# Cortex_A35 register map
Vendor: ARM Ltd.; File version: 1.1
Registers are 32-bit, read-write, no defined reset value unless marked. A register's access mark holds for its fields unless they carry their own. Offsets are from the block's base; [hi:lo] are bit positions; {n}, {i} and the like mark numbered series; 'fields as' and 'values as' point back to an identical list.

## ETM0
Base 0x4A240000
Same registers: ETM1 0x4A340000
0x04 TRC_PRGCTLR
  [0] EN — Name of field: EN
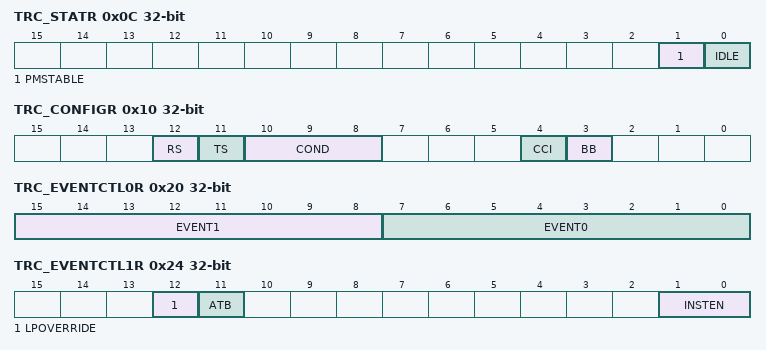
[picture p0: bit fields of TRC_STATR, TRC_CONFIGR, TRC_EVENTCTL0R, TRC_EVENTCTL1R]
0x0C TRC_STATR
  [1] PMSTABLE — Name of field: PMSTABLE
  [0] IDLE — Name of field: IDLE
0x10 TRC_CONFIGR
  [12] RS — Name of field: RS
  [11] TS — Name of field: TS
  [10:8] COND — Name of field: COND
  [4] CCI — Name of field: CCI
  [3] BB — Name of field: BB
0x20 TRC_EVENTCTL0R
  [15:8] EVENT1 — Name of field: EVENT1
  [7:0] EVENT0 — Name of field: EVENT0
0x24 TRC_EVENTCTL1R
  [12] LPOVERRIDE — Name of field: LPOVERRIDE
  [11] ATB — Name of field: ATB
  [1:0] INSTEN — Name of field: INSTEN
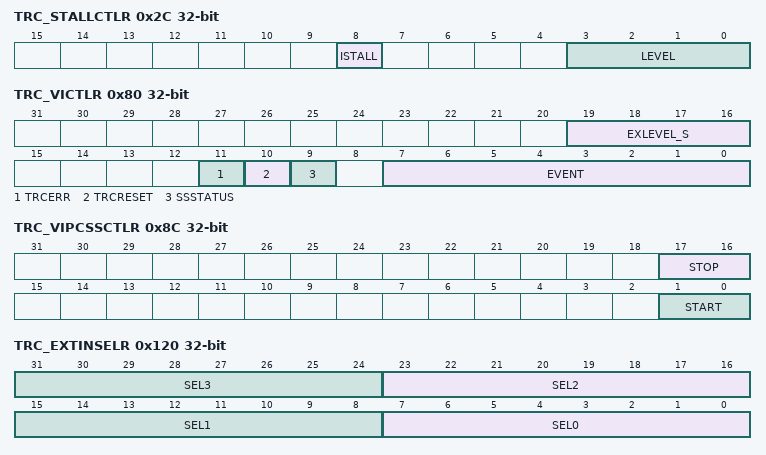
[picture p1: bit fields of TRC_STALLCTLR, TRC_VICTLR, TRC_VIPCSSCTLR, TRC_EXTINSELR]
0x2C TRC_STALLCTLR
  [8] ISTALL — Name of field: ISTALL
  [3:0] LEVEL — Name of field: LEVEL
0x30 TRC_TSCTLR
  [7:0] EVENT — Name of field: EVENT
0x34 TRC_SYNCPR
  [4:0] PERIOD — Name of field: PERIOD
0x38 TRC_CCCTLR
  [11:0] THRESHOLD — Name of field: THRESHOLD
0x40 TRC_TRACEIDR
  [6:0] TRACEID — Name of field: TRACEID
0x80 TRC_VICTLR
  [19:16] EXLEVEL_S — Name of field: EXLEVEL_S
  [11] TRCERR — Name of field: TRCERR
  [10] TRCRESET — Name of field: TRCRESET
  [9] SSSTATUS — Name of field: SSSTATUS
  [7:0] EVENT — Name of field: EVENT
0x8C TRC_VIPCSSCTLR
  [17:16] STOP — Name of field: STOP
  [1:0] START — Name of field: START
0x120 TRC_EXTINSELR
  [8n+7:8n] SEL{n} (n=0..3) — Name of field: SEL{n}
0x140 TRC_CNTRLDVR0
  [15:0] VALUE — Name of field: VALUE
0x180 TRC_IDR8
  [31:0] MAXSPEC — Name of field: MAXSPEC
0x184 TRC_IDR9
  [31:0] NUMP0KEY — Name of field: NUMP0KEY
0x188 TRC_IDR10
  [31:0] NUMP1KEY — Name of field: NUMP1KEY
0x18C TRC_IDR11
  [31:0] NUMP1SPC — Name of field: NUMP1SPC
0x190 TRC_IDR12
  [31:0] NUMCONDKEY — Name of field: NUMCONDKEY
0x194 TRC_IDR13
  [31:0] NUMCONDSPC — Name of field: NUMCONDSPC
0x1C0 TRC_IMSPEC0
  [3:0] SUPPORT — Name of field: SUPPORT
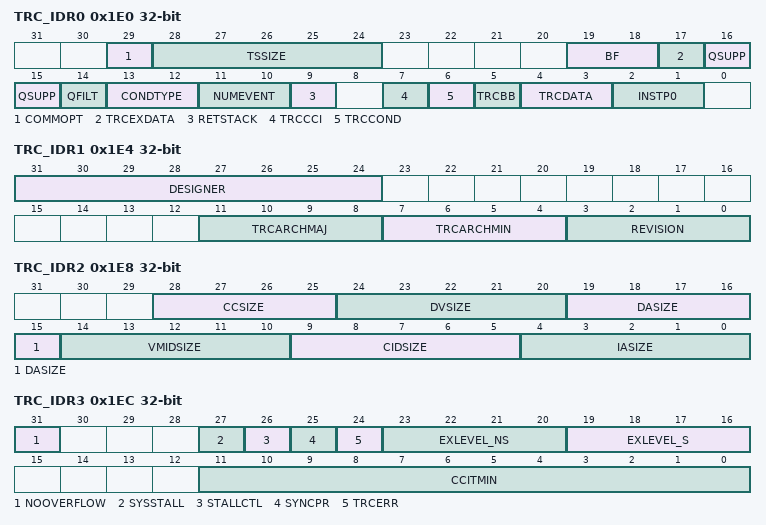
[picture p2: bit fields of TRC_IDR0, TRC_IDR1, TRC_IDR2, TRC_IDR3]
0x1E0 TRC_IDR0
  [29] COMMOPT — Name of field: COMMOPT
  [28:24] TSSIZE — Name of field: TSSIZE
  [19:18] BF — Name of field: BF
  [17] TRCEXDATA — Name of field: TRCEXDATA
  [16:15] QSUPP — Name of field: QSUPP
  [14] QFILT — Name of field: QFILT
  [13:12] CONDTYPE — Name of field: CONDTYPE
  [11:10] NUMEVENT — Name of field: NUMEVENT
  [9] RETSTACK — Name of field: RETSTACK
  [7] TRCCCI — Name of field: TRCCCI
  [6] TRCCOND — Name of field: TRCCOND
  [5] TRCBB — Name of field: TRCBB
  [4:3] TRCDATA — Name of field: TRCDATA
  [2:1] INSTP0 — Name of field: INSTP0
0x1E4 TRC_IDR1
  [31:24] DESIGNER — Name of field: DESIGNER
  [11:8] TRCARCHMAJ — Name of field: TRCARCHMAJ
  [7:4] TRCARCHMIN — Name of field: TRCARCHMIN
  [3:0] REVISION — Name of field: REVISION
0x1E8 TRC_IDR2
  [28:25] CCSIZE — Name of field: CCSIZE
  [24:20] DVSIZE — Name of field: DVSIZE
  [19:15] DASIZE — Name of field: DASIZE
  [14:10] VMIDSIZE — Name of field: VMIDSIZE
  [9:5] CIDSIZE — Name of field: CIDSIZE
  [4:0] IASIZE — Name of field: IASIZE
0x1EC TRC_IDR3
  [31] NOOVERFLOW — Name of field: NOOVERFLOW
  [27] SYSSTALL — Name of field: SYSSTALL
  [26] STALLCTL — Name of field: STALLCTL
  [25] SYNCPR — Name of field: SYNCPR
  [24] TRCERR — Name of field: TRCERR
  [23:20] EXLEVEL_NS — Name of field: EXLEVEL_NS
  [19:16] EXLEVEL_S — Name of field: EXLEVEL_S
  [11:0] CCITMIN — Name of field: CCITMIN
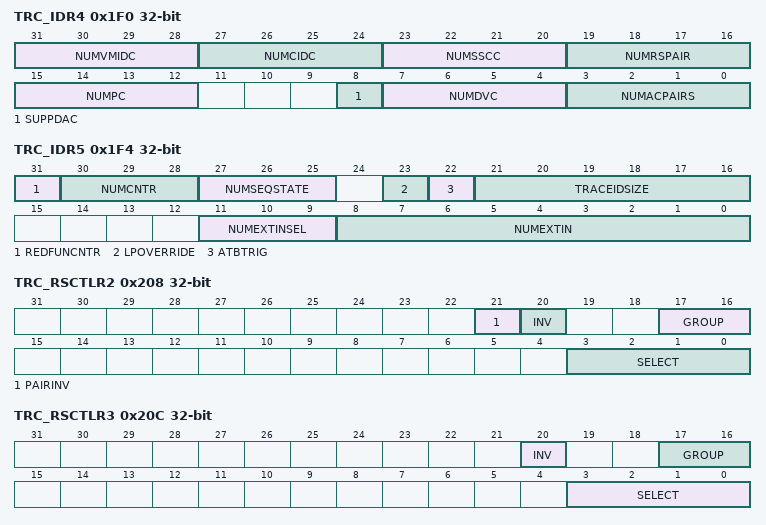
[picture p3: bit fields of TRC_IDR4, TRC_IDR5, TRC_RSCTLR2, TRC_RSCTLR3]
0x1F0 TRC_IDR4
  [31:28] NUMVMIDC — Name of field: NUMVMIDC
  [27:24] NUMCIDC — Name of field: NUMCIDC
  [23:20] NUMSSCC — Name of field: NUMSSCC
  [19:16] NUMRSPAIR — Name of field: NUMRSPAIR
  [15:12] NUMPC — Name of field: NUMPC
  [8] SUPPDAC — Name of field: SUPPDAC
  [7:4] NUMDVC — Name of field: NUMDVC
  [3:0] NUMACPAIRS — Name of field: NUMACPAIRS
0x1F4 TRC_IDR5
  [31] REDFUNCNTR — Name of field: REDFUNCNTR
  [30:28] NUMCNTR — Name of field: NUMCNTR
  [27:25] NUMSEQSTATE — Name of field: NUMSEQSTATE
  [23] LPOVERRIDE — Name of field: LPOVERRIDE
  [22] ATBTRIG — Name of field: ATBTRIG
  [21:16] TRACEIDSIZE — Name of field: TRACEIDSIZE
  [11:9] NUMEXTINSEL — Name of field: NUMEXTINSEL
  [8:0] NUMEXTIN — Name of field: NUMEXTIN
0x208 TRC_RSCTLR2
  [21] PAIRINV — Name of field: PAIRINV
  [20] INV — Name of field: INV
  [17:16] GROUP — Name of field: GROUP
  [3:0] SELECT — Name of field: SELECT
0x20C TRC_RSCTLR3
  [20] INV — Name of field: INV
  [17:16] GROUP — Name of field: GROUP
  [3:0] SELECT — Name of field: SELECT
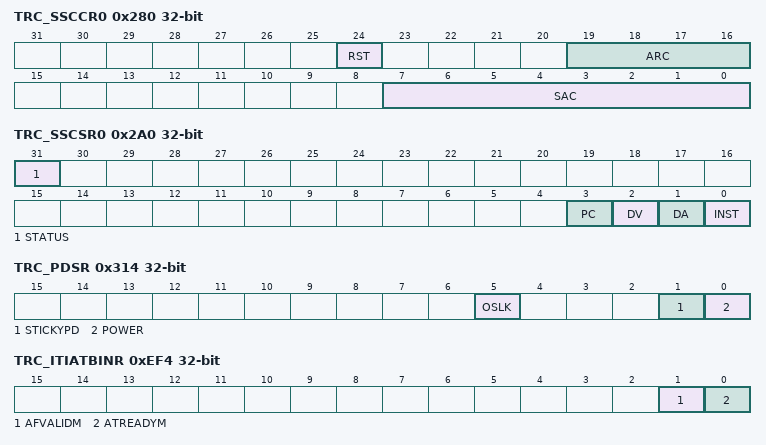
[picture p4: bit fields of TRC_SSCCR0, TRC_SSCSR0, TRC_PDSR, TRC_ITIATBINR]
0x280 TRC_SSCCR0
  [24] RST — Name of field: RST
  [19:16] ARC — Name of field: ARC
  [7:0] SAC — Name of field: SAC
0x2A0 TRC_SSCSR0
  [31] STATUS — Name of field: STATUS
  [3] PC — Name of field: PC
  [2] DV — Name of field: DV
  [1] DA — Name of field: DA
  [0] INST — Name of field: INST
0x2C0 TRC_SSPCICR0
  [3:0] PC — Name of field: PC
0x310 TRC_PDCR
  [3] PU — Name of field: PU
0x314 TRC_PDSR
  [5] OSLK — Name of field: OSLK
  [1] STICKYPD — Name of field: STICKYPD
  [0] POWER — Name of field: POWER
0xEE4 TRC_ITATBIDR
  [6:0] ID — Name of field: ID
0xEEC TRC_ITIDATAR
  [6:0] DATA — Name of field: DATA
0xEF4 TRC_ITIATBINR
  [1] AFVALIDM — Name of field: AFVALIDM
  [0] ATREADYM — Name of field: ATREADYM
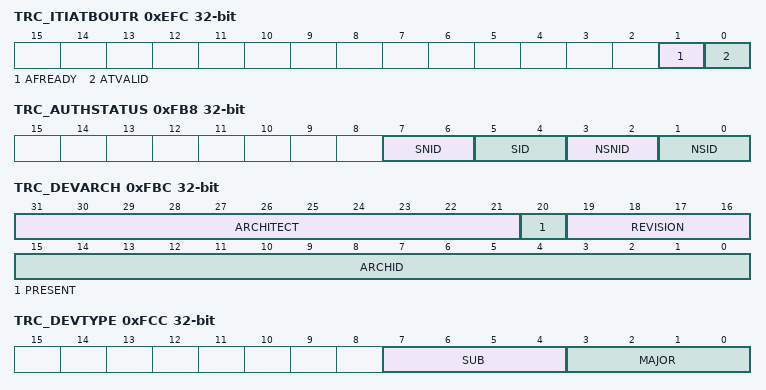
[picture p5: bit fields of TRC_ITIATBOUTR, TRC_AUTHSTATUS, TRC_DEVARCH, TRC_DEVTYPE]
0xEFC TRC_ITIATBOUTR
  [1] AFREADY — Name of field: AFREADY
  [0] ATVALID — Name of field: ATVALID
0xF00 TRC_ITCTRL
  [0] IME — Name of field: IME
0xFA0 TRC_CLAIMSET
  [3:0] SET — Name of field: SET
0xFA4 TRC_CLAIMCLR
  [3:0] CLR — Name of field: CLR
0xFB8 TRC_AUTHSTATUS
  [7:6] SNID — Name of field: SNID
  [5:4] SID — Name of field: SID
  [3:2] NSNID — Name of field: NSNID
  [1:0] NSID — Name of field: NSID
0xFBC TRC_DEVARCH
  [31:21] ARCHITECT — Name of field: ARCHITECT
  [20] PRESENT — Name of field: PRESENT
  [19:16] REVISION — Name of field: REVISION
  [15:0] ARCHID — Name of field: ARCHID
0xFCC TRC_DEVTYPE
  [7:4] SUB — Name of field: SUB
  [3:0] MAJOR — Name of field: MAJOR
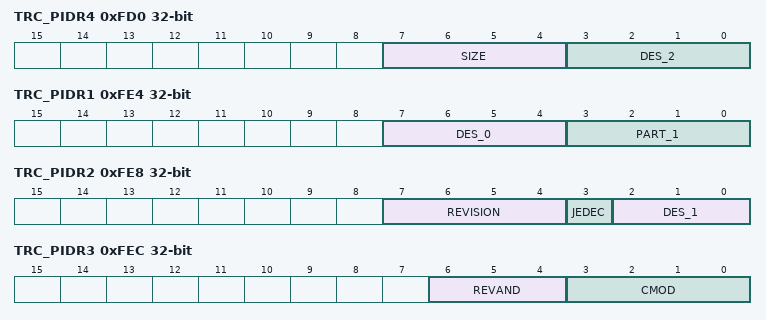
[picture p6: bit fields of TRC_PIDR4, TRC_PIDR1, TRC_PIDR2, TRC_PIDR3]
0xFD0 TRC_PIDR4
  [7:4] SIZE — Name of field: SIZE
  [3:0] DES_2 — Name of field: DES_2
0xFE0 TRC_PIDR0
  [7:0] PART_0 — Name of field: PART_0
0xFE4 TRC_PIDR1
  [7:4] DES_0 — Name of field: DES_0
  [3:0] PART_1 — Name of field: PART_1
0xFE8 TRC_PIDR2
  [7:4] REVISION — Name of field: REVISION
  [3] JEDEC — Name of field: JEDEC
  [2:0] DES_1 — Name of field: DES_1
0xFEC TRC_PIDR3
  [6:4] REVAND — Name of field: REVAND
  [3:0] CMOD — Name of field: CMOD

## PMU0
Base 0x4A230000
Same registers: PMU1 0x4A330000
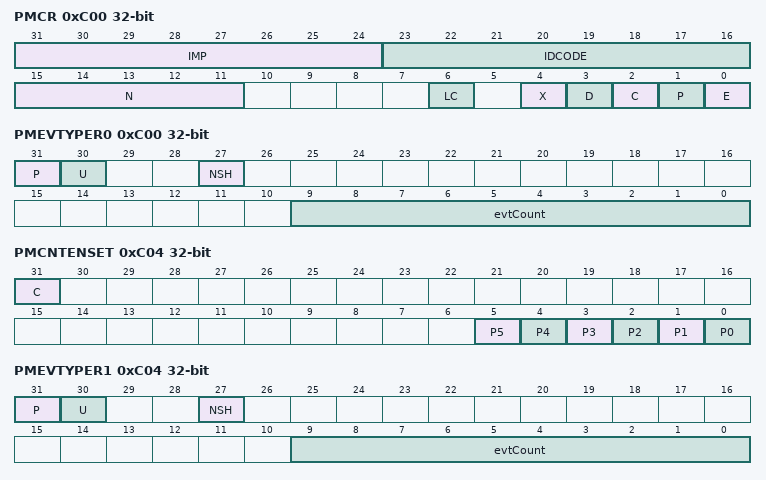
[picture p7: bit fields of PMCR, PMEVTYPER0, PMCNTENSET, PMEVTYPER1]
0xC00 PMCR
  [31:24] IMP — Name of field: IMP
  [23:16] IDCODE — Name of field: IDCODE
  [15:11] N — Name of field: N
  [6] LC — Name of field: LC
  [4] X — Name of field: X
  [3] D — Name of field: D
  [2] C — Name of field: C
  [1] P — Name of field: P
  [0] E — Name of field: E
0xC00 PMEVTYPER0 (alternate view of PMCR)
  [31] P — Name of field: P
  [30] U — Name of field: U
  [27] NSH — Name of field: NSH
  [9:0] evtCount — Name of field: evtCount
0xC04 PMCNTENSET
  [31] C — Name of field: C
  [n] P{n} (n=0..5) — Name of field: P{n}
0xC04 PMEVTYPER1 (alternate view of PMCNTENSET)
  fields as PMEVTYPER0
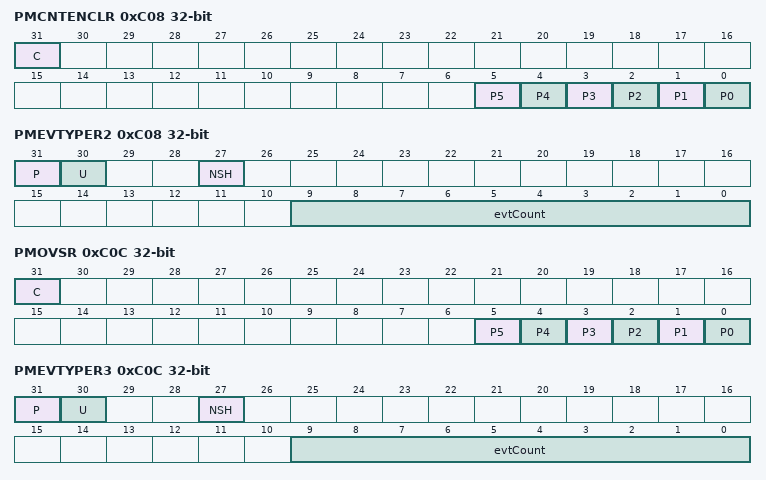
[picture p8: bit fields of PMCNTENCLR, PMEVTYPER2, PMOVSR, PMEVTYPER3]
0xC08 PMCNTENCLR
  [31] C — Name of field: C
  [n] P{n} (n=0..5) — Name of field: P{n}
0xC08 PMEVTYPER2 (alternate view of PMCNTENCLR)
  fields as PMEVTYPER0
0xC0C PMOVSR
  [31] C — Name of field: C
  [n] P{n} (n=0..5) — Name of field: P{n}
0xC0C PMEVTYPER3 (alternate view of PMOVSR)
  fields as PMEVTYPER0
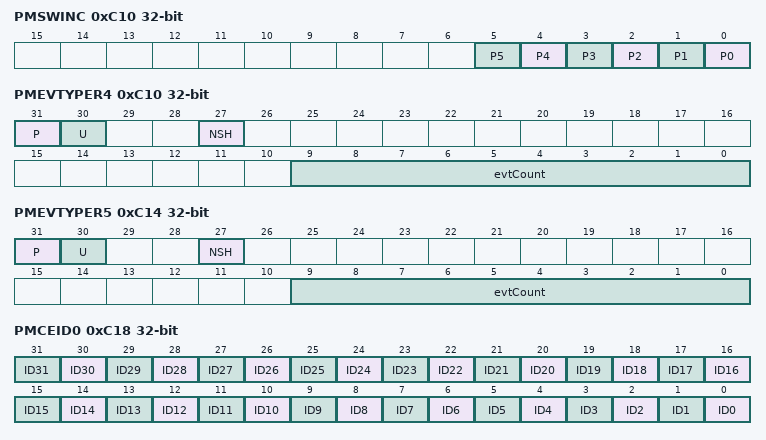
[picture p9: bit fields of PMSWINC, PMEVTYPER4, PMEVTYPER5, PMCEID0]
0xC10 PMSWINC
  [n] P{n} (n=0..5) — Name of field: P{n}
0xC10 PMEVTYPER4 (alternate view of PMSWINC)
  fields as PMEVTYPER0
0xC14 PMSELR
  [4:0] SEL — Name of field: SEL
0xC14 PMEVTYPER5 (alternate view of PMSELR)
  fields as PMEVTYPER0
0xC18 PMCEID0
  [n] ID{n} (n=0..31) — Name of field: ID{n}
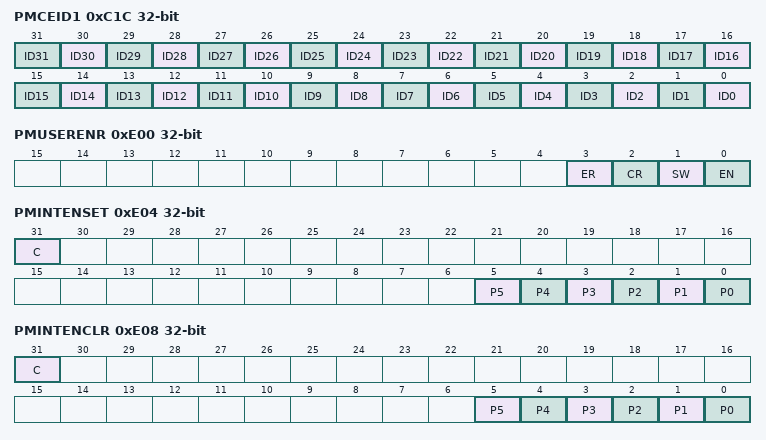
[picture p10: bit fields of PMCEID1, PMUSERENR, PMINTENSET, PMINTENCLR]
0xC1C PMCEID1
  [n] ID{n} (n=0..31) — Name of field: ID{n}
0xE00 PMUSERENR
  [3] ER — Name of field: ER
  [2] CR — Name of field: CR
  [1] SW — Name of field: SW
  [0] EN — Name of field: EN
0xE04 PMINTENSET
  [31] C — Name of field: C
  [n] P{n} (n=0..5) — Name of field: P{n}
0xE08 PMINTENCLR
  [31] C — Name of field: C
  [n] P{n} (n=0..5) — Name of field: P{n}
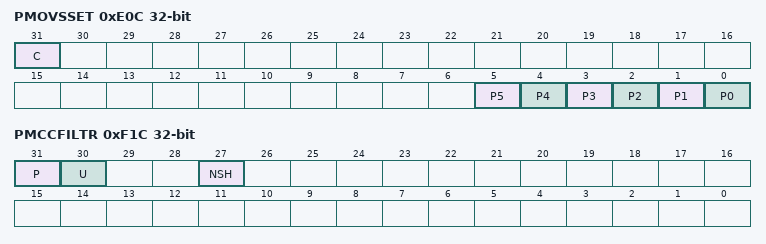
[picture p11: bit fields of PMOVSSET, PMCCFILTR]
0xE0C PMOVSSET
  [31] C — Name of field: C
  [n] P{n} (n=0..5) — Name of field: P{n}
0xF1C PMCCFILTR
  [31] P — Name of field: P
  [30] U — Name of field: U
  [27] NSH — Name of field: NSH
